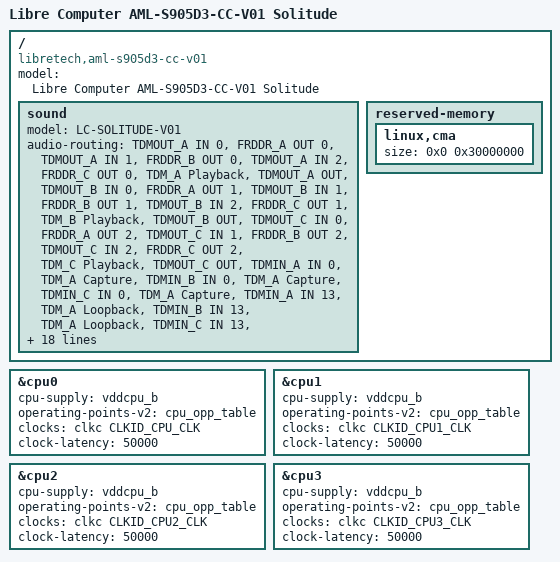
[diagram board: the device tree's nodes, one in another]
// SPDX-License-Identifier: (GPL-2.0+ OR MIT)
/*
 * Libre Computer AML-S905D3-CC-V01 (Solitude V0.1 pre-production)
 */

/dts-v1/;

#include <dt-bindings/clock/g12a-clkc.h>
#include "meson-sm1.dtsi"
#include "meson-libretech-cottonwood.dtsi"
#include "meson-libretech-cottonwood-v01.dtsi"
#include "meson-g12-vendor-firmware.dtsi"
#include "meson-libretech-ramoops.dtsi"

/ {
	compatible = "libretech,aml-s905d3-cc-v01", "amlogic,sm1";
	model = "Libre Computer AML-S905D3-CC-V01 Solitude";

	sound {
		model = "LC-SOLITUDE-V01";
		audio-routing = "TDMOUT_A IN 0", "FRDDR_A OUT 0",
				"TDMOUT_A IN 1", "FRDDR_B OUT 0",
				"TDMOUT_A IN 2", "FRDDR_C OUT 0",
				"TDM_A Playback", "TDMOUT_A OUT",
				"TDMOUT_B IN 0", "FRDDR_A OUT 1",
				"TDMOUT_B IN 1", "FRDDR_B OUT 1",
				"TDMOUT_B IN 2", "FRDDR_C OUT 1",
				"TDM_B Playback", "TDMOUT_B OUT",
				"TDMOUT_C IN 0", "FRDDR_A OUT 2",
				"TDMOUT_C IN 1", "FRDDR_B OUT 2",
				"TDMOUT_C IN 2", "FRDDR_C OUT 2",
				"TDM_C Playback", "TDMOUT_C OUT",
				"TDMIN_A IN 0", "TDM_A Capture",
				"TDMIN_B IN 0", "TDM_A Capture",
				"TDMIN_C IN 0", "TDM_A Capture",
				"TDMIN_A IN 13", "TDM_A Loopback",
				"TDMIN_B IN 13", "TDM_A Loopback",
				"TDMIN_C IN 13", "TDM_A Loopback",
				"TDMIN_A IN 1", "TDM_B Capture",
				"TDMIN_B IN 1", "TDM_B Capture",
				"TDMIN_C IN 1", "TDM_B Capture",
				"TDMIN_A IN 14", "TDM_B Loopback",
				"TDMIN_B IN 14", "TDM_B Loopback",
				"TDMIN_C IN 14", "TDM_B Loopback",
				"TDMIN_A IN 2", "TDM_C Capture",
				"TDMIN_B IN 2", "TDM_C Capture",
				"TDMIN_C IN 2", "TDM_C Capture",
				"TDMIN_A IN 15", "TDM_C Loopback",
				"TDMIN_B IN 15", "TDM_C Loopback",
				"TDMIN_C IN 15", "TDM_C Loopback",
				"TODDR_A IN 0", "TDMIN_A OUT",
				"TODDR_B IN 0", "TDMIN_A OUT",
				"TODDR_C IN 0", "TDMIN_A OUT",
				"TODDR_A IN 1", "TDMIN_B OUT",
				"TODDR_B IN 1", "TDMIN_B OUT",
				"TODDR_C IN 1", "TDMIN_B OUT",
				"TODDR_A IN 2", "TDMIN_C OUT",
				"TODDR_B IN 2", "TDMIN_C OUT",
				"TODDR_C IN 2", "TDMIN_C OUT",
				"Lineout", "ACODEC LOLP",
				"Lineout", "ACODEC LORP";
	};
};

&cpu0 {
	cpu-supply = <&vddcpu_b>;
	operating-points-v2 = <&cpu_opp_table>;
	clocks = <&clkc CLKID_CPU_CLK>;
	clock-latency = <50000>;
};

&cpu1 {
	cpu-supply = <&vddcpu_b>;
	operating-points-v2 = <&cpu_opp_table>;
	clocks = <&clkc CLKID_CPU1_CLK>;
	clock-latency = <50000>;
};

&cpu2 {
	cpu-supply = <&vddcpu_b>;
	operating-points-v2 = <&cpu_opp_table>;
	clocks = <&clkc CLKID_CPU2_CLK>;
	clock-latency = <50000>;
};

&cpu3 {
	cpu-supply = <&vddcpu_b>;
	operating-points-v2 = <&cpu_opp_table>;
	clocks = <&clkc CLKID_CPU3_CLK>;
	clock-latency = <50000>;
};

/ {
	reserved-memory {
		linux,cma {
			/*
			 * AML-S905D3-CC-V01 comes in up to 4 GiB RAM variants.
			 * U-Boot's meson_fixup_cma_size() writes min(this
			 * value, 7/32 of detected RAM) here and forces
			 * alloc-ranges to the first 1 GiB, so this value is the
			 * binding clamp whenever it is the smaller term.
			 *
			 * 768 MiB, not the 896 MiB the 7/32 formula yields at
			 * 4 GiB: the sub-1 GiB window is not 1 GiB wide.
			 * secmon, ramoops and the kernel image leave ~820 MiB
			 * of largest free run below 0x40000000, and 896 MiB was
			 * measured failing on both A311D and S905D3. A failed
			 * reservation costs the whole pool -- one pr_err, then
			 * CONFIG_CMA_SIZE_MBYTES=128 -- so over-asking loses
			 * 640 MiB rather than gaining 128.
			 */
			size = <0x0 0x30000000>;
		};
	};
};
